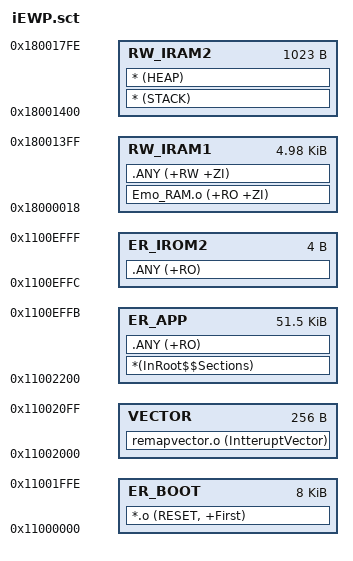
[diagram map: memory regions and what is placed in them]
; *************************************************************
; *** Scatter-Loading Description File generated by uVision ***
; *************************************************************

LR_IROM1 0x11002200 0x0000CDFC  {    ; load region size_region
    ER_APP 0x11002200 0x0000CDFC {  ; load address = execution address
        *(InRoot$$Sections)
		.ANY (+RO)
    }

    RW_IRAM1 0x18000018 0x000013E8  {  ; RW data
        Emo_RAM.o (+RO +ZI)
        .ANY (+RW +ZI)
    }

    RW_IRAM2 0x18001400 0x000003FF  {  ; RW data
        * (STACK)                                        ; stack size = 0x3F0
        * (HEAP)                                          ; Heap size = 0x000
    }
}

LR_IROM2 0x11000000 0x00001FFF  {
    ER_BOOT 0x11000000 0x00001FFF {
        *.o (RESET, +First)  
    }
}

LR_IROM3 0x1100EFFC 0x00000004  {
    ER_IROM2 0x1100EFFC 0x00000004  {
        .ANY (+RO)
    }
}

LR_IROM4 0x11002000 0x00000200  {
    VECTOR 0x11002000 0x00000100  {
		remapvector.o (IntteruptVector)
    }

}
